# STM32N657 register map
File version: 1.0
CPU: CM55 r0p1, little endian, no MPU, FPU, vendor SysTick, 8 interrupt priority bits
Registers are 32-bit, read-write, reset 0x0 unless marked. A register's access mark holds for its fields unless they carry their own. Offsets are from the block's base; [hi:lo] are bit positions.

## LPUART1 — Low-power universal asynchronous receiver transmitter
Base 0x46000C00
Same registers: LPUART1_S 0x56000C00
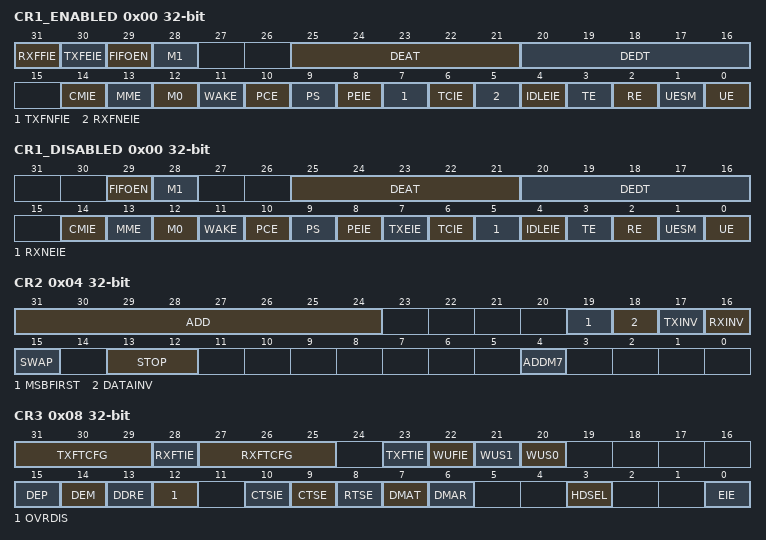
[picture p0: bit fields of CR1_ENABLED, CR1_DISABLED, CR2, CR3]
0x00 CR1_ENABLED — LPUART control register 1
  [31] RXFFIE — RXFIFO Full interrupt enable
  [30] TXFEIE — TXFIFO empty interrupt enable
  [29] FIFOEN — FIFO mode enable
  [28] M1 — Word length
  [25:21] DEAT — Driver Enable assertion time
  [20:16] DEDT — Driver Enable deassertion time
  [14] CMIE — Character match interrupt enable
  [13] MME — Mute mode enable
  [12] M0 — Word length
  [11] WAKE — Receiver wake-up method
  [10] PCE — Parity control enable
  [9] PS — Parity selection
  [8] PEIE — PE interrupt enable
  [7] TXFNFIE — TXFIFO not full interrupt enable
  [6] TCIE — Transmission complete interrupt enable
  [5] RXFNEIE — RXFIFO not empty interrupt enable
  [4] IDLEIE — IDLE interrupt enable
  [3] TE — Transmitter enable
  [2] RE — Receiver enable
  [1] UESM — LPUART enable in low-power mode
  [0] UE — LPUART enable
0x00 CR1_DISABLED (alternate view of CR1_ENABLED) — LPUART control register 1
  [29] FIFOEN — FIFO mode enable
  [28] M1 — Word length
  [25:21] DEAT — Driver Enable assertion time
  [20:16] DEDT — Driver Enable deassertion time
  [14] CMIE — Character match interrupt enable
  [13] MME — Mute mode enable
  [12] M0 — Word length
  [11] WAKE — Receiver wake-up method
  [10] PCE — Parity control enable
  [9] PS — Parity selection
  [8] PEIE — PE interrupt enable
  [7] TXEIE — Transmit data register empty
  [6] TCIE — Transmission complete interrupt enable
  [5] RXNEIE — Receive data register not empty
  [4] IDLEIE — IDLE interrupt enable
  [3] TE — Transmitter enable
  [2] RE — Receiver enable
  [1] UESM — LPUART enable in low-power mode
  [0] UE — LPUART enable
0x04 CR2 — LPUART control register 2
  [31:24] ADD — Address of the LPUART node
  [19] MSBFIRST — Most significant bit first
  [18] DATAINV — Binary data inversion
  [17] TXINV — TX pin active level inversion
  [16] RXINV — RX pin active level inversion
  [15] SWAP — Swap TX/RX pins
  [13:12] STOP — STOP bits
  [4] ADDM7 — 7-bit Address Detection/4-bit Address Detection
0x08 CR3 — LPUART control register 3
  [31:29] TXFTCFG — TXFIFO threshold configuration
  [28] RXFTIE — RXFIFO threshold interrupt enable
  [27:25] RXFTCFG — Receive FIFO threshold configuration
  [23] TXFTIE — TXFIFO threshold interrupt enable
  [22] WUFIE — Wake-up from low-power mode interrupt enable
  [21] WUS1 — Wake-up from low-power mode interrupt flag selection
  [20] WUS0 — Wake-up from low-power mode interrupt flag selection
  [15] DEP — Driver enable polarity selection
  [14] DEM — Driver enable mode
  [13] DDRE — DMA Disable on Reception Error
  [12] OVRDIS — Overrun Disable
  [10] CTSIE — CTS interrupt enable
  [9] CTSE — CTS enable
  [8] RTSE — RTS enable
  [7] DMAT — DMA enable transmitter
  [6] DMAR — DMA enable receiver
  [3] HDSEL — Half-duplex selection
  [0] EIE — Error interrupt enable
0x0C BRR — LPUART baud rate register
  [19:0] BRR — LPUART baud rate division (LPUARTDIV)
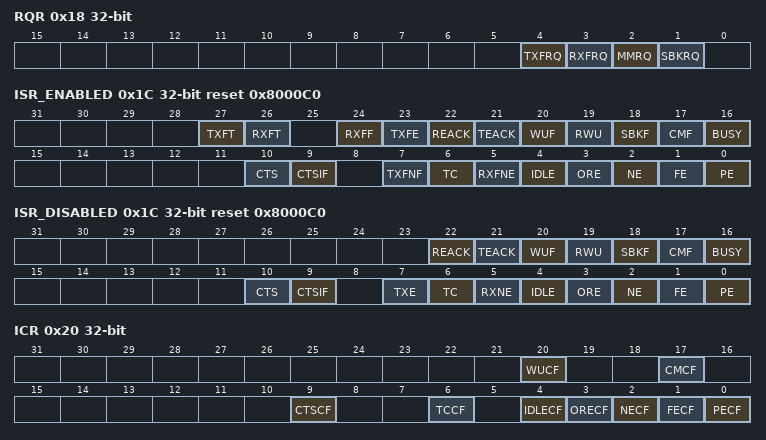
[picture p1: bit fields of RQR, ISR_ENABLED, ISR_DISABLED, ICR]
0x18 RQR wo — LPUART request register
  [4] TXFRQ — Transmit data flush request
  [3] RXFRQ — Receive data flush request
  [2] MMRQ — Mute mode request
  [1] SBKRQ — Send break request
0x1C ISR_ENABLED ro reset 0x8000C0 — LPUART interrupt and status register
  [27] TXFT — TXFIFO threshold flag
  [26] RXFT — RXFIFO threshold flag
  [24] RXFF — RXFIFO Full
  [23] TXFE — TXFIFO Empty
  [22] REACK — Receive enable acknowledge flag
  [21] TEACK — Transmit enable acknowledge flag
  [20] WUF — Wake-up from low-power mode flag
  [19] RWU — Receiver wake-up from Mute mode
  [18] SBKF — Send break flag
  [17] CMF — Character match flag
  [16] BUSY — Busy flag
  [10] CTS — CTS flag
  [9] CTSIF — CTS interrupt flag
  [7] TXFNF — TXFIFO not full
  [6] TC — Transmission complete
  [5] RXFNE — RXFIFO not empty
  [4] IDLE — Idle line detected
  [3] ORE — Overrun error
  [2] NE — Start bit noise detection flag
  [1] FE — Framing error
  [0] PE — Parity error
0x1C ISR_DISABLED ro reset 0x8000C0 (alternate view of ISR_ENABLED) — LPUART interrupt and status register
  [22] REACK — Receive enable acknowledge flag
  [21] TEACK — Transmit enable acknowledge flag
  [20] WUF — Wake-up from low-power mode flag
  [19] RWU — Receiver wake-up from Mute mode
  [18] SBKF — Send break flag
  [17] CMF — Character match flag
  [16] BUSY — Busy flag
  [10] CTS — CTS flag
  [9] CTSIF — CTS interrupt flag
  [7] TXE — Transmit data register empty
  [6] TC — Transmission complete
  [5] RXNE — Read data register not empty
  [4] IDLE — Idle line detected
  [3] ORE — Overrun error
  [2] NE — Start bit noise detection flag
  [1] FE — Framing error
  [0] PE — Parity error
0x20 ICR wo — LPUART interrupt flag clear register
  [20] WUCF — Wake-up from low-power mode clear flag
  [17] CMCF — Character match clear flag
  [9] CTSCF — CTS clear flag
  [6] TCCF — Transmission complete clear flag
  [4] IDLECF — Idle line detected clear flag
  [3] ORECF — Overrun error clear flag
  [2] NECF — Noise detected clear flag
  [1] FECF — Framing error clear flag
  [0] PECF — Parity error clear flag
0x24 RDR ro — LPUART receive data register
  [8:0] RDR — Receive data value
0x28 TDR — LPUART transmit data register
  [8:0] TDR — Transmit data value
0x2C PRESC — LPUART prescaler register
  [3:0] PRESCALER — Clock prescaler
